# AVR64DU28 register map
Vendor: Atmel; File version: 1.0
CPU: other r0p0, little endian, no MPU, no FPU, 4 interrupt priority bits
Registers are 8-bit, read-write, reset 0x0 unless marked. A register's access mark holds for its fields unless they carry their own. Offsets are from the block's base; [hi:lo] are bit positions; {n}, {i} and the like mark numbered series; 'fields as' and 'values as' point back to an identical list.

## CPU
Base 0x00800034
0x00 CCP — Configuration Change Protection
  [7:0] CCP — CCP signature
    157=SPM (SPM Instruction Protection); 216=IOREG (IO Register Protection)
0x09 SP 16-bit (reset mask 0xFF) — Stack Pointer
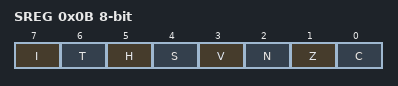
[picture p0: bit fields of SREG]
0x0B SREG — Status Register
  [7] I — Global Interrupt Enable Flag
  [6] T — Transfer Bit
  [5] H — Half Carry Flag
  [4] S — N Exclusive Or V Flag
  [3] V — Two's Complement Overflow Flag
  [2] N — Negative Flag
  [1] Z — Zero Flag
  [0] C — Carry Flag

## CPUINT — Interrupt Controller
Base 0x00800110
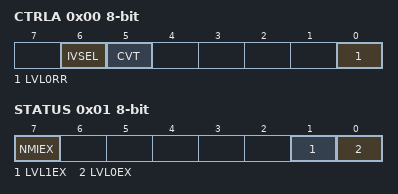
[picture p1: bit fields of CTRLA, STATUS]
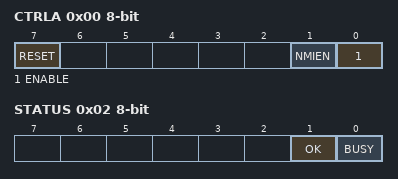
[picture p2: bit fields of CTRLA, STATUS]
0x00 CTRLA — Control A
  [6] IVSEL — Interrupt Vector Select
  [5] CVT — Compact Vector Table
  [0] LVL0RR — Round-robin Scheduling Enable
0x01 STATUS ro
  [7] NMIEX — Non-maskable Interrupt Executing
  [1] LVL1EX — Level 1 Interrupt Executing
  [0] LVL0EX — Level 0 Interrupt Executing
0x02 LVL0PRI — Interrupt Level 0 Priority
  [7:0] LVL0PRI — Interrupt Level Priority
0x03 LVL1VEC — Interrupt Level 1 Priority Vector
  [7:0] LVL1VEC — Interrupt Vector with High Priority

## CRCSCAN
Base 0x00800120
0x00 CTRLA — Control A
  [7] RESET — Reset CRC scan
  [1] NMIEN — Enable NMI Trigger
  [0] ENABLE — Enable CRC scan
0x01 CTRLB — Control B
  [1:0] SRC — CRC Source
    0=FLASH (CRC on entire flash); 1=BOOTAPP (CRC on boot and appl section of flash); 2=BOOT (CRC on boot section of flash)
0x02 STATUS ro
  [1] OK — CRC Ok
  [0] BUSY — CRC Busy

## EVSYS — Event System
Base 0x00800200
0x00 SWEVENTA — Software Event A
  [7:0] SWEVENTA wo — Software event on channel select
    1=CH0 (Software event on channel 0); 2=CH1 (Software event on channel 1); 4=CH2 (Software event on channel 2); 8=CH3 (Software event on channel 3); 16=CH4 (Software event on channel 4); 32=CH5 (Software event on channel 5); 64=CH6 (Software event on channel 6); 128=CH7 (Software event on channel 7)
{0x10+i} CHANNEL{i} (i=0..5) — Multiplexer Channel {i}
  [7:0] CHANNEL — Channel generator select
    0=OFF; 1=UPDI_SYNCH (UPDI SYNCH Character); 6=RTC_OVF (Real Time Counter Overflow); 7=RTC_CMP (Real Time Counter Compare); 8=RTC_EVGEN0 (Real Time Counter Event Output 0); 9=RTC_EVGEN1 (Real Time Counter Event Output 1); {v}=CCL_LUT{v-16} (Configurable Custom Logic LUT{v-16}) (v=16..19); 32=AC0_OUT (Analog Comparator 0 Out); 36=ADC0_RESRDY (ADC0 Result Ready); 37=ADC0_SAMPRDY (ADC0 Sample Ready); 38=ADC0_WCMP (ADC0 Window Comparator); 64=PORTA_EVGEN0 (Port A Event 0); 65=PORTA_EVGEN1 (Port A Event 1); 68=PORTC_EVGEN0 (Port C Event 0); 69=PORTC_EVGEN1 (Port C Event 1); 70=PORTD_EVGEN0 (Port D Event 0); 71=PORTD_EVGEN1 (Port D Event 1); 74=PORTF_EVGEN0 (Port F Event 0); 75=PORTF_EVGEN1 (Port F Event 1); 96=USART0_XCK; 97=USART1_XCK; 104=SPI0_SCK; 128=TCA0_OVF_LUNF (Timer/Counter A0 Overflow / Low Byte Timer Underflow); 129=TCA0_HUNF (Timer/Counter A0 High Byte Timer Underflow); 132=TCA0_CMP0_LCMP0 (Timer/Counter A0 Compare 0 / Low Byte Compare 0); 133=TCA0_CMP1_LCMP1 (Timer/Counter A0 Compare 1 / Low Byte Compare 1); 134=TCA0_CMP2_LCMP2 (Timer/Counter A0 Compare 2 / Low Byte Compare 2); 160=TCB0_CAPT (Timer/Counter B0 Capture); 161=TCB0_OVF (Timer/Counter B0 Overflow); 162=TCB1_CAPT (Timer/Counter B1 Capture); 163=TCB1_OVF (Timer/Counter B1 Overflow); 192=USB0_SETUP (USB0 Setup Received); 193=USB0_SOF (USB0 SOF Received); 194=USB0_CRC (USB0 CRC Error); 195=USB0_UNFOVF (USB0 Underflow / Overflow); 196=USB0_RX (USB0 Data Byte Received); 197=USB0_TX (USB0 Data Byte Transmitted)
{0x20+2i} USERCCLLUT{i}A (i=0..3) — CCL{i} Event A
  [7:0] USER — User channel select
    0=OFF; {v}=CHANNEL{v-1} (Connect user to event channel {v-1}) (v=1..6)
{0x21+2i} USERCCLLUT{i}B (i=0..3) — CCL{i} Event B
  fields as USERCCLLUT0A
0x28 USERADC0START — ADC0
  fields as USERCCLLUT0A
0x29 USEREVSYSEVOUTA — EVOUTA
  fields as USERCCLLUT0A
0x2A USEREVSYSEVOUTD — EVOUTD
  fields as USERCCLLUT0A
0x2B USEREVSYSEVOUTF — EVOUTF
  fields as USERCCLLUT0A
0x2C USERUSART0IRDA — USART0
  fields as USERCCLLUT0A
0x2D USERUSART1IRDA — USART1
  fields as USERCCLLUT0A
0x2E USERTCA0CNTA — TCA0 Event A
  fields as USERCCLLUT0A
0x2F USERTCA0CNTB — TCA0 Event B
  fields as USERCCLLUT0A
0x30 USERTCB0CAPT — TCB0 Event A
  fields as USERCCLLUT0A
0x31 USERTCB0COUNT — TCB0 Event B
  fields as USERCCLLUT0A
0x32 USERTCB1CAPT — TCB1 Event A
  fields as USERCCLLUT0A
0x33 USERTCB1COUNT — TCB1 Event B
  fields as USERCCLLUT0A
